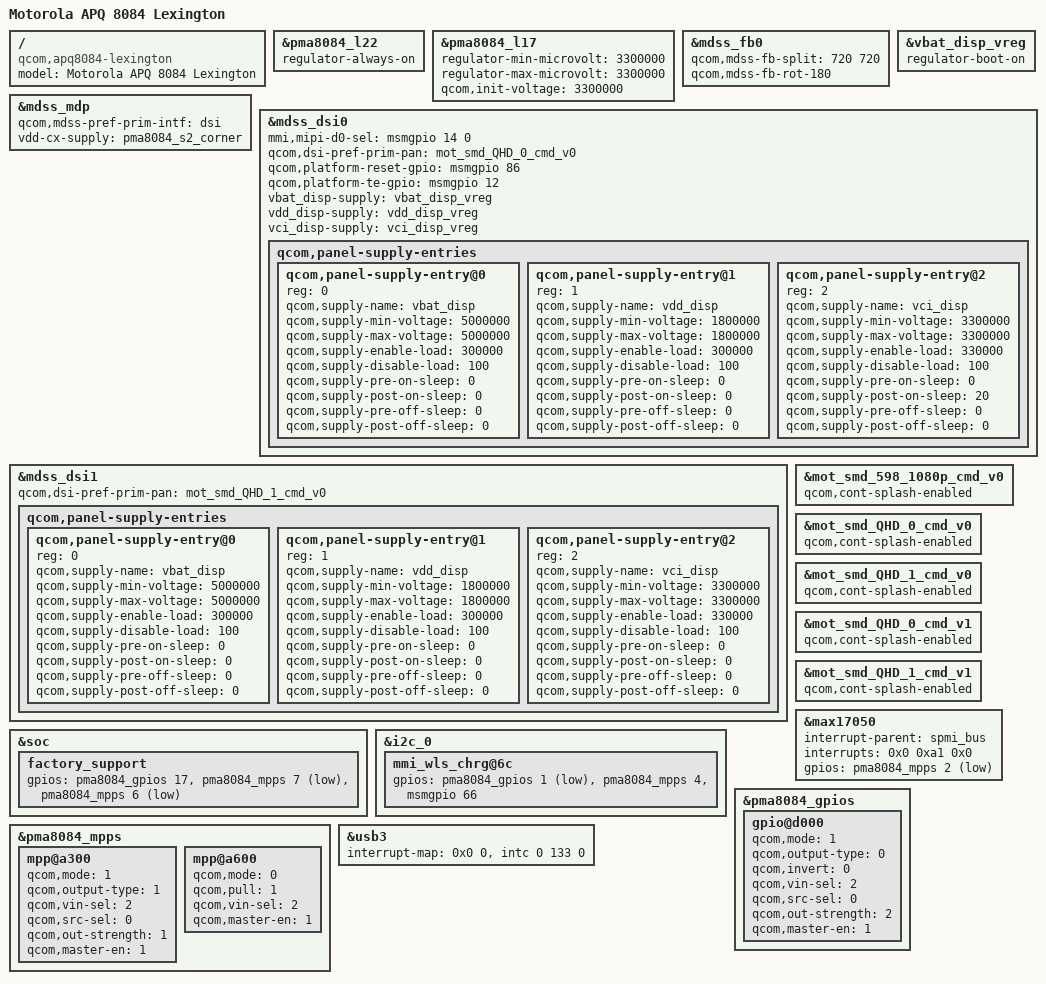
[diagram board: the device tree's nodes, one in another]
/* Copyright (c) 2013, The Linux Foundation. All rights reserved.
 * Copyright (c) 2014 Motorola Mobility LLC
 *
 * This program is free software; you can redistribute it and/or modify
 * it under the terms of the GNU General Public License version 2 and
 * only version 2 as published by the Free Software Foundation.
 *
 * This program is distributed in the hope that it will be useful,
 * but WITHOUT ANY WARRANTY; without even the implied warranty of
 * MERCHANTABILITY or FITNESS FOR A PARTICULAR PURPOSE.  See the
 * GNU General Public License for more details.
 */

#include "apq8084-moto-common.dtsi"
#include "apq8084-mot-camera-sensor.dtsi"
#include "dsi-panel-mot-dummy-qhd-video.dtsi"
#include "dsi-panel-mot-smd-QHD-cmd.dtsi"
#include "dsi-panel-mot-smd-720p-cmd.dtsi"
#include "dsi-panel-mot-smd-598-1080p-cmd.dtsi"

/ {
	model = "Motorola APQ 8084 Lexington";
	compatible = "qcom,apq8084-lexington",
		   "qcom,apq8084-moto",
		   "qcom,apq8084";
};

&pma8084_l22 {
	regulator-always-on;
};

&pma8084_l17 {
	regulator-min-microvolt = <3300000>;
	regulator-max-microvolt = <3300000>;
	qcom,init-voltage = <3300000>;
};

&mdss_fb0 {
	qcom,mdss-fb-split = <720 720>;
	qcom,mdss-fb-rot-180;
};

&vbat_disp_vreg {
        regulator-boot-on;
};

&mdss_mdp {
	qcom,mdss-pref-prim-intf = "dsi";
	vdd-cx-supply = <&pma8084_s2_corner>;
};

&mdss_dsi0 {
	mmi,mipi-d0-sel = <&msmgpio 14 0>;
	qcom,dsi-pref-prim-pan = <&mot_smd_QHD_0_cmd_v0>;
	qcom,platform-reset-gpio = <&msmgpio 86 0>;
	qcom,platform-te-gpio = <&msmgpio 12 0>;
	vbat_disp-supply = <&vbat_disp_vreg>;
	vdd_disp-supply = <&vdd_disp_vreg>;
	vci_disp-supply = <&vci_disp_vreg>;
	/delete-property/ vdd-supply;
	qcom,panel-supply-entries {
		#address-cells = <1>;
		#size-cells = <0>;
		qcom,panel-supply-entry@0 {
			reg = <0>;
			qcom,supply-name = "vbat_disp";
			qcom,supply-min-voltage = <5000000>;
			qcom,supply-max-voltage = <5000000>;
			qcom,supply-enable-load = <300000>;
			qcom,supply-disable-load = <100>;
			qcom,supply-pre-on-sleep = <0>;
			qcom,supply-post-on-sleep = <0>;
			qcom,supply-pre-off-sleep = <0>;
			qcom,supply-post-off-sleep = <0>;
		};
		qcom,panel-supply-entry@1 {
			reg = <1>;
			qcom,supply-name = "vdd_disp";
			qcom,supply-min-voltage = <1800000>;
			qcom,supply-max-voltage = <1800000>;
			qcom,supply-enable-load = <300000>;
			qcom,supply-disable-load = <100>;
			qcom,supply-pre-on-sleep = <0>;
			qcom,supply-post-on-sleep = <0>;
			qcom,supply-pre-off-sleep = <0>;
			qcom,supply-post-off-sleep = <0>;
		};
		qcom,panel-supply-entry@2 {
			reg = <2>;
			qcom,supply-name = "vci_disp";
			qcom,supply-min-voltage = <3300000>;
			qcom,supply-max-voltage = <3300000>;
			qcom,supply-enable-load = <330000>;
			qcom,supply-disable-load = <100>;
			qcom,supply-pre-on-sleep = <0>;
			qcom,supply-post-on-sleep = <20>;
			qcom,supply-pre-off-sleep = <0>;
			qcom,supply-post-off-sleep = <0>;
		};
	};
};

&mdss_dsi1 {
	qcom,dsi-pref-prim-pan = <&mot_smd_QHD_1_cmd_v0>;
	/delete-property/ vdd-supply;
	qcom,panel-supply-entries {
		#address-cells = <1>;
		#size-cells = <0>;
		qcom,panel-supply-entry@0 {
			reg = <0>;
			qcom,supply-name = "vbat_disp";
			qcom,supply-min-voltage = <5000000>;
			qcom,supply-max-voltage = <5000000>;
			qcom,supply-enable-load = <300000>;
			qcom,supply-disable-load = <100>;
			qcom,supply-pre-on-sleep = <0>;
			qcom,supply-post-on-sleep = <0>;
			qcom,supply-pre-off-sleep = <0>;
			qcom,supply-post-off-sleep = <0>;
		};
		qcom,panel-supply-entry@1 {
			reg = <1>;
			qcom,supply-name = "vdd_disp";
			qcom,supply-min-voltage = <1800000>;
			qcom,supply-max-voltage = <1800000>;
			qcom,supply-enable-load = <300000>;
			qcom,supply-disable-load = <100>;
			qcom,supply-pre-on-sleep = <0>;
			qcom,supply-post-on-sleep = <0>;
			qcom,supply-pre-off-sleep = <0>;
			qcom,supply-post-off-sleep = <0>;
		};
		qcom,panel-supply-entry@2 {
			reg = <2>;
			qcom,supply-name = "vci_disp";
			qcom,supply-min-voltage = <3300000>;
			qcom,supply-max-voltage = <3300000>;
			qcom,supply-enable-load = <330000>;
			qcom,supply-disable-load = <100>;
			qcom,supply-pre-on-sleep = <0>;
			qcom,supply-post-on-sleep = <0>;
			qcom,supply-pre-off-sleep = <0>;
			qcom,supply-post-off-sleep = <0>;
		};
	};
};

&mot_smd_598_1080p_cmd_v0 {
	qcom,cont-splash-enabled;
};


&mot_smd_QHD_0_cmd_v0 {
        qcom,cont-splash-enabled;
};

&mot_smd_QHD_1_cmd_v0 {
        qcom,cont-splash-enabled;
};

&mot_smd_QHD_0_cmd_v1 {
	qcom,cont-splash-enabled;
};

&mot_smd_QHD_1_cmd_v1 {
	qcom,cont-splash-enabled;
};


&max17050 {
	interrupt-parent = <&spmi_bus>;
	interrupts = <0x0 0xa1 0x0>;    /* PMA8084 MPP 2 */
	gpios = <&pma8084_mpps 2 0x11>;  /* GPIOF_DIR_IN|GPIOF_EXPORT */
};

&soc {
	factory_support {
		gpios = <&pma8084_gpios 17 0x0>, /* GPIOF_OUT_INIT_LOW */
			<&pma8084_mpps 7 0x1>, /* GPIOF_IN */
			<&pma8084_mpps 6 0x1>; /* GPIOF_IN */
	};
};

&i2c_0 {
	mmi_wls_chrg@6c {
		gpios = <&pma8084_gpios 1 0x1>, /* GPIOF_IN */
			<&pma8084_mpps 4 0x2>, /* GPIOF_OUT_INIT_HIGH */
			<&msmgpio 66 0x0>; /* GPIOF_OUT_INIT_LOW */
	};
};

&pma8084_gpios {
	gpio@d000 { /* GPIO 17 */
		qcom,mode = <1>;		/* Digital output */
		qcom,output-type = <0>;		/* CMOS logic */
		qcom,invert = <0>;		/* Output low initially */
		qcom,vin-sel = <2>;		/* VIN 2 */
		qcom,src-sel = <0>;		/* GPIO */
		qcom,out-strength = <2>;	/* Medium */
		qcom,master-en = <1>;		/* Enable GPIO */
	};
};

&pma8084_mpps {
	mpp@a300 { /* MPP 4 */
		/* Wireless Charge Complete N */
		qcom,mode = <1>;		/* Digital output */
		qcom,output-type = <1>;		/* Open Drain NMOS logic */
		qcom,vin-sel = <2>;		/* VIN 2 */
		qcom,src-sel = <0>;		/* Constant */
		qcom,out-strength = <1>;	/* Low */
		qcom,master-en = <1>;		/* Enable GPIO */
	};
	mpp@a600 { /* MPP 7 */
		qcom,mode = <0>;          /* QPNP_PIN_MODE_DIG_IN */
		qcom,pull = <1>;	/* No pull */
		qcom,vin-sel = <2>;
		qcom,master-en = <1>;
	};
};

&usb3 {
	interrupt-map = <0x0 0 &intc 0 133 0>;
	interrupt-names = "hs_phy_irq";
};
